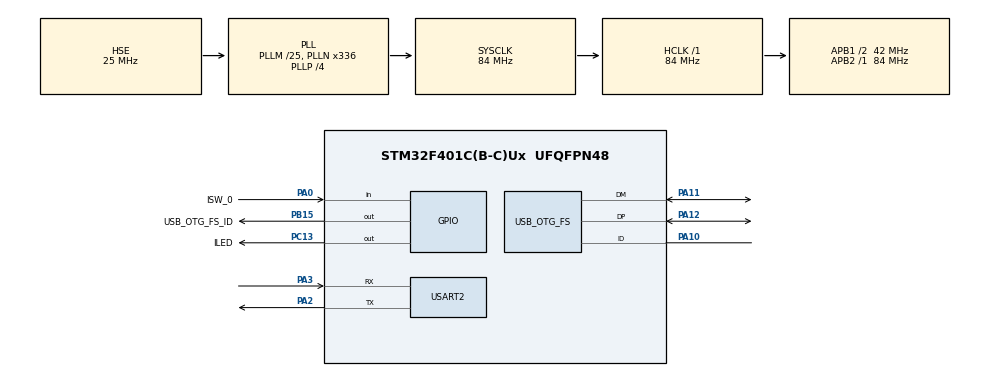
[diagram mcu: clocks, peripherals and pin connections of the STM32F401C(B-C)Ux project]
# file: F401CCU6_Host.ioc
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AL94.I-CUBE-USBD-COMPOSITE.1.0.3._USBD_USE_HS=false
Mcu.Family=STM32F4
Mcu.Name=STM32F401C(B-C)Ux
Mcu.Package=UFQFPN48
NVIC.PriorityGroup=NVIC_PRIORITYGROUP_4
PA0-WKUP.GPIO_Label=ISW_0
PA0-WKUP.Signal=GPIO_Input
PA10.Mode=OTG/Dual_Role_Device
PA10.Signal=USB_OTG_FS_ID
PA11.Mode=OTG/Dual_Role_Device
PA11.Signal=USB_OTG_FS_DM
PA12.Mode=OTG/Dual_Role_Device
PA12.Signal=USB_OTG_FS_DP
PA13.Mode=Serial_Wire
PA13.Signal=SYS_JTMS-SWDIO
PA14.Mode=Serial_Wire
PA14.Signal=SYS_JTCK-SWCLK
PA2.Mode=Asynchronous
PA2.Signal=USART2_TX
PA3.Mode=Asynchronous
PA3.Signal=USART2_RX
PB15.GPIO_Label=USB_OTG_FS_ID
PB15.GPIO_Speed=GPIO_SPEED_FREQ_VERY_HIGH
PB15.Signal=GPIO_Output
PC13-ANTI_TAMP.GPIO_Label=ILED
PC13-ANTI_TAMP.GPIO_PuPd=GPIO_NOPULL
PC13-ANTI_TAMP.GPIO_Speed=GPIO_SPEED_FREQ_LOW
PC13-ANTI_TAMP.PinState=GPIO_PIN_RESET
PC13-ANTI_TAMP.Signal=GPIO_Output
PC14-OSC32_IN.Mode=LSE-External-Oscillator
PC14-OSC32_IN.Signal=RCC_OSC32_IN
PC15-OSC32_OUT.Mode=LSE-External-Oscillator
PC15-OSC32_OUT.Signal=RCC_OSC32_OUT
PH0\ -\ OSC_IN.Mode=HSE-External-Oscillator
PH0\ -\ OSC_IN.Signal=RCC_OSC_IN
PH1\ -\ OSC_OUT.Mode=HSE-External-Oscillator
PH1\ -\ OSC_OUT.Signal=RCC_OSC_OUT
ProjectManager.HeapSize=0x200
ProjectManager.StackSize=0x400
ProjectManager.TargetToolchain=STM32CubeIDE
RCC.48MHZClocksFreq_Value=48000000
RCC.AHBFreq_Value=84000000
RCC.APB1CLKDivider=RCC_HCLK_DIV2
RCC.APB1Freq_Value=42000000
RCC.APB1TimFreq_Value=84000000
RCC.APB2Freq_Value=84000000
RCC.APB2TimFreq_Value=84000000
RCC.CortexFreq_Value=84000000
RCC.HCLKFreq_Value=84000000
RCC.HSE_VALUE=25000000
RCC.HSI_VALUE=16000000
RCC.PLLM=25
RCC.PLLN=336
RCC.PLLP=RCC_PLLP_DIV4
RCC.PLLQ=7
RCC.SYSCLKFreq_VALUE=84000000
RCC.SYSCLKSource=RCC_SYSCLKSOURCE_PLLCLK
RCC.VCOOutputFreq_Value=336000000
USART2.VirtualMode=VM_ASYNC
VP_CRC_VS_CRC.Mode=CRC_Activate
board=custom

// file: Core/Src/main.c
/* USER CODE BEGIN Header */
/**
  ******************************************************************************
  * @file           : main.c
  * @brief          : Main program body
  ******************************************************************************
  * @attention
  *
  * Copyright (c) 2023 STMicroelectronics.
  * All rights reserved.
  *
  * This software is licensed under terms that can be found in the LICENSE file
  * in the root directory of this software component.
  * If no LICENSE file comes with this software, it is provided AS-IS.
  *
  ******************************************************************************
  */
/* USER CODE END Header */
#include "main.h"

/* USER CODE BEGIN PD */
#define LED_ON()   HAL_GPIO_WritePin(ILED_GPIO_Port, ILED_Pin, GPIO_PIN_RESET);
#define LED_OFF()   HAL_GPIO_WritePin(ILED_GPIO_Port, ILED_Pin, GPIO_PIN_SET);
/* USER CODE END PD */

CRC_HandleTypeDef hcrc;

UART_HandleTypeDef huart2;

/* USER CODE BEGIN PV */
uint8_t rData[16];
uint8_t tData[16] = "Hello";
/* USER CODE END PV */

void SystemClock_Config(void);
static void MX_GPIO_Init(void);
static void MX_CRC_Init(void);
static void MX_USART2_UART_Init(void);
static void MX_USB_OTG_FS_USB_Init(void);

int main(void)
{

  /* MCU Configuration--------------------------------------------------------*/

  /* Reset of all peripherals, Initializes the Flash interface and the Systick. */
  HAL_Init();

  /* Configure the system clock */
  SystemClock_Config();

  /* Initialize all configured peripherals */
  MX_GPIO_Init();
  MX_CRC_Init();
  MX_USART2_UART_Init();
  MX_USB_OTG_FS_USB_Init();

  /* Infinite loop */
  /* USER CODE BEGIN WHILE */
  while (1)
  {
	if(HAL_GPIO_ReadPin(ISW_0_GPIO_Port, ISW_0_Pin) == GPIO_PIN_RESET){ //on
		LED_ON();
	    HAL_UART_Transmit(&huart2, tData, sizeof(tData) / sizeof(uint8_t), 1000);
	    LED_OFF();
	}

    /* USER CODE END WHILE */

  }
}

void SystemClock_Config(void)
{
  RCC_OscInitTypeDef RCC_OscInitStruct = {0};
  RCC_ClkInitTypeDef RCC_ClkInitStruct = {0};

  /** Configure the main internal regulator output voltage
  */
  __HAL_RCC_PWR_CLK_ENABLE();
  __HAL_PWR_VOLTAGESCALING_CONFIG(PWR_REGULATOR_VOLTAGE_SCALE2);

  /** Initializes the RCC Oscillators according to the specified parameters
  * in the RCC_OscInitTypeDef structure.
  */
  RCC_OscInitStruct.OscillatorType = RCC_OSCILLATORTYPE_HSE;
  RCC_OscInitStruct.HSEState = RCC_HSE_ON;
  RCC_OscInitStruct.PLL.PLLState = RCC_PLL_ON;
  RCC_OscInitStruct.PLL.PLLSource = RCC_PLLSOURCE_HSE;
  RCC_OscInitStruct.PLL.PLLM = 25;
  RCC_OscInitStruct.PLL.PLLN = 336;
  RCC_OscInitStruct.PLL.PLLP = RCC_PLLP_DIV4;
  RCC_OscInitStruct.PLL.PLLQ = 7;
  if (HAL_RCC_OscConfig(&RCC_OscInitStruct) != HAL_OK)
  {
    Error_Handler();
  }

  /** Initializes the CPU, AHB and APB buses clocks
  */
  RCC_ClkInitStruct.ClockType = RCC_CLOCKTYPE_HCLK|RCC_CLOCKTYPE_SYSCLK
                              |RCC_CLOCKTYPE_PCLK1|RCC_CLOCKTYPE_PCLK2;
  RCC_ClkInitStruct.SYSCLKSource = RCC_SYSCLKSOURCE_PLLCLK;
  RCC_ClkInitStruct.AHBCLKDivider = RCC_SYSCLK_DIV1;
  RCC_ClkInitStruct.APB1CLKDivider = RCC_HCLK_DIV2;
  RCC_ClkInitStruct.APB2CLKDivider = RCC_HCLK_DIV1;

  if (HAL_RCC_ClockConfig(&RCC_ClkInitStruct, FLASH_LATENCY_2) != HAL_OK)
  {
    Error_Handler();
  }
}

static void MX_CRC_Init(void)
{

  hcrc.Instance = CRC;
  if (HAL_CRC_Init(&hcrc) != HAL_OK)
  {
    Error_Handler();
  }

}

static void MX_USART2_UART_Init(void)
{

  huart2.Instance = USART2;
  huart2.Init.BaudRate = 115200;
  huart2.Init.WordLength = UART_WORDLENGTH_8B;
  huart2.Init.StopBits = UART_STOPBITS_1;
  huart2.Init.Parity = UART_PARITY_NONE;
  huart2.Init.Mode = UART_MODE_TX_RX;
  huart2.Init.HwFlowCtl = UART_HWCONTROL_NONE;
  huart2.Init.OverSampling = UART_OVERSAMPLING_16;
  if (HAL_UART_Init(&huart2) != HAL_OK)
  {
    Error_Handler();
  }

}

static void MX_USB_OTG_FS_USB_Init(void)
{

}

static void MX_GPIO_Init(void)
{
  GPIO_InitTypeDef GPIO_InitStruct = {0};

  /* GPIO Ports Clock Enable */
  __HAL_RCC_GPIOC_CLK_ENABLE();
  __HAL_RCC_GPIOH_CLK_ENABLE();
  __HAL_RCC_GPIOA_CLK_ENABLE();
  __HAL_RCC_GPIOB_CLK_ENABLE();

  /*Configure GPIO pin Output Level */
  HAL_GPIO_WritePin(ILED_GPIO_Port, ILED_Pin, GPIO_PIN_RESET);

  /*Configure GPIO pin Output Level */
  HAL_GPIO_WritePin(USB_OTG_FS_ID_GPIO_Port, USB_OTG_FS_ID_Pin, GPIO_PIN_RESET);

  /*Configure GPIO pin : ILED_Pin */
  GPIO_InitStruct.Pin = ILED_Pin;
  GPIO_InitStruct.Mode = GPIO_MODE_OUTPUT_PP;
  GPIO_InitStruct.Pull = GPIO_NOPULL;
  GPIO_InitStruct.Speed = GPIO_SPEED_FREQ_LOW;
  HAL_GPIO_Init(ILED_GPIO_Port, &GPIO_InitStruct);

  /*Configure GPIO pin : ISW_0_Pin */
  GPIO_InitStruct.Pin = ISW_0_Pin;
  GPIO_InitStruct.Mode = GPIO_MODE_INPUT;
  GPIO_InitStruct.Pull = GPIO_NOPULL;
  HAL_GPIO_Init(ISW_0_GPIO_Port, &GPIO_InitStruct);

  /*Configure GPIO pin : USB_OTG_FS_ID_Pin */
  GPIO_InitStruct.Pin = USB_OTG_FS_ID_Pin;
  GPIO_InitStruct.Mode = GPIO_MODE_OUTPUT_PP;
  GPIO_InitStruct.Pull = GPIO_NOPULL;
  GPIO_InitStruct.Speed = GPIO_SPEED_FREQ_VERY_HIGH;
  HAL_GPIO_Init(USB_OTG_FS_ID_GPIO_Port, &GPIO_InitStruct);

  /*Configure GPIO pins : PA10 PA11 PA12 */
  GPIO_InitStruct.Pin = GPIO_PIN_10|GPIO_PIN_11|GPIO_PIN_12;
  GPIO_InitStruct.Mode = GPIO_MODE_AF_PP;
  GPIO_InitStruct.Pull = GPIO_NOPULL;
  GPIO_InitStruct.Speed = GPIO_SPEED_FREQ_VERY_HIGH;
  GPIO_InitStruct.Alternate = GPIO_AF10_OTG_FS;
  HAL_GPIO_Init(GPIOA, &GPIO_InitStruct);

}

/* USER CODE BEGIN 4 */
void HAL_UART_RxCpltCallback(UART_HandleTypeDef *huart)
{
  //HAL_UART_Receive_IT(&huart2, rData, 1);
}
/* USER CODE END 4 */

void Error_Handler(void)
{
  __disable_irq();
  while (1)
  {
  }
}
